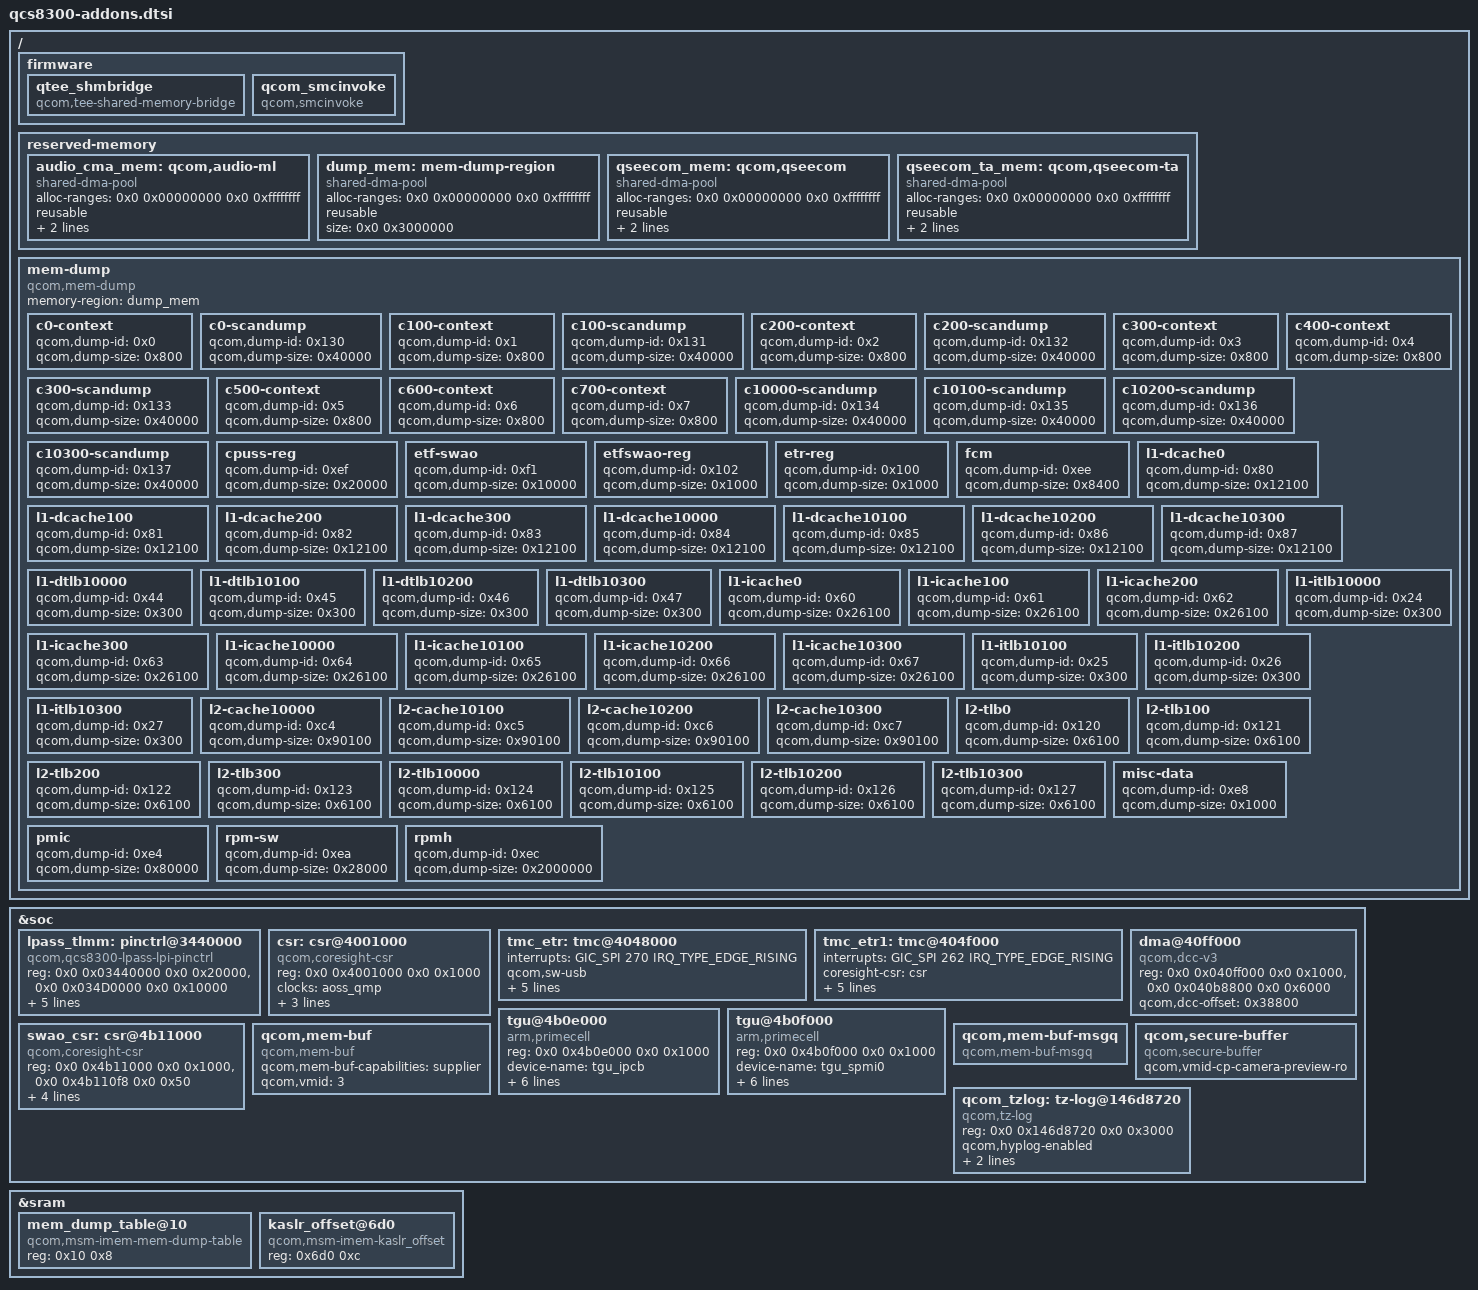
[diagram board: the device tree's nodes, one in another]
// SPDX-License-Identifier: BSD-3-Clause
/*
 * Copyright (c) 2024 Qualcomm Innovation Center, Inc. All rights reserved.
 */

#include "qcs8300-dma-heaps.dtsi"
/ {
	firmware {
		qtee_shmbridge {
			compatible = "qcom,tee-shared-memory-bridge";
		};

		qcom_smcinvoke {
			compatible = "qcom,smcinvoke";
		};
	};

	reserved-memory {
		audio_cma_mem: qcom,audio-ml {
			compatible = "shared-dma-pool";
			alloc-ranges = <0x0 0x00000000 0x0 0xffffffff>;
			reusable;
			alignment = <0x0 0x400000>;
			size = <0x0 0x1000000>;
		};

		dump_mem: mem-dump-region {
			compatible = "shared-dma-pool";
			alloc-ranges = <0x0 0x00000000 0x0 0xffffffff>;
			reusable;
			size = <0x0 0x3000000>;
		};

		qseecom_mem: qcom,qseecom {
			compatible = "shared-dma-pool";
			alloc-ranges = <0x0 0x00000000 0x0 0xffffffff>;
			reusable;
			alignment = <0x0 0x400000>;
			size = <0x0 0x1400000>; /* 20M */
		};

		qseecom_ta_mem: qcom,qseecom-ta {
			compatible = "shared-dma-pool";
			alloc-ranges = <0x0 0x00000000 0x0 0xffffffff>;
			reusable;
			alignment = <0x0 0x400000>;
			size = <0x0 0x1000000>; /* 16M */
		};
	};

	mem-dump {
		compatible = "qcom,mem-dump";
		memory-region = <&dump_mem>;

		c0-context {
			qcom,dump-id = <0x0>;
			qcom,dump-size = <0x800>;
		};

		c0-scandump {
			qcom,dump-id = <0x130>;
			qcom,dump-size = <0x40000>;
		};

		c100-context {
			qcom,dump-id = <0x1>;
			qcom,dump-size = <0x800>;
		};

		c100-scandump {
			qcom,dump-id = <0x131>;
			qcom,dump-size = <0x40000>;
		};

		c200-context {
			qcom,dump-id = <0x2>;
			qcom,dump-size = <0x800>;
		};

		c200-scandump {
			qcom,dump-id = <0x132>;
			qcom,dump-size = <0x40000>;
		};

		c300-context {
			qcom,dump-id = <0x3>;
			qcom,dump-size = <0x800>;
		};

		c300-scandump {
			qcom,dump-id = <0x133>;
			qcom,dump-size = <0x40000>;
		};

		c400-context {
			qcom,dump-id = <0x4>;
			qcom,dump-size = <0x800>;
		};

		c500-context {
			qcom,dump-id = <0x5>;
			qcom,dump-size = <0x800>;
		};

		c600-context {
			qcom,dump-id = <0x6>;
			qcom,dump-size = <0x800>;
		};

		c700-context {
			qcom,dump-id = <0x7>;
			qcom,dump-size = <0x800>;
		};

		c10000-scandump {
			qcom,dump-id = <0x134>;
			qcom,dump-size = <0x40000>;
		};

		c10100-scandump {
			qcom,dump-id = <0x135>;
			qcom,dump-size = <0x40000>;
		};

		c10200-scandump {
			qcom,dump-id = <0x136>;
			qcom,dump-size = <0x40000>;
		};

		c10300-scandump {
			qcom,dump-id = <0x137>;
			qcom,dump-size = <0x40000>;
		};

		cpuss-reg {
			qcom,dump-id = <0xef>;
			qcom,dump-size = <0x20000>;
		};

		etf-swao {
			qcom,dump-id = <0xf1>;
			qcom,dump-size = <0x10000>;
		};

		etfswao-reg {
			qcom,dump-id = <0x102>;
			qcom,dump-size = <0x1000>;
		};

		etr-reg {
			qcom,dump-id = <0x100>;
			qcom,dump-size = <0x1000>;
		};

		fcm {
			qcom,dump-id = <0xee>;
			qcom,dump-size = <0x8400>;
		};

		l1-dcache0 {
			qcom,dump-id = <0x80>;
			qcom,dump-size = <0x12100>;
		};

		l1-dcache100 {
			qcom,dump-id = <0x81>;
			qcom,dump-size = <0x12100>;
		};

		l1-dcache200 {
			qcom,dump-id = <0x82>;
			qcom,dump-size = <0x12100>;
		};

		l1-dcache300 {
			qcom,dump-id = <0x83>;
			qcom,dump-size = <0x12100>;
		};

		l1-dcache10000 {
			qcom,dump-id = <0x84>;
			qcom,dump-size = <0x12100>;
		};

		l1-dcache10100 {
			qcom,dump-id = <0x85>;
			qcom,dump-size = <0x12100>;
		};

		l1-dcache10200 {
			qcom,dump-id = <0x86>;
			qcom,dump-size = <0x12100>;
		};

		l1-dcache10300 {
			qcom,dump-id = <0x87>;
			qcom,dump-size = <0x12100>;
		};

		l1-dtlb10000 {
			qcom,dump-id = <0x44>;
			qcom,dump-size = <0x300>;
		};

		l1-dtlb10100 {
			qcom,dump-id = <0x45>;
			qcom,dump-size = <0x300>;
		};

		l1-dtlb10200 {
			qcom,dump-id = <0x46>;
			qcom,dump-size = <0x300>;
		};

		l1-dtlb10300 {
			qcom,dump-id = <0x47>;
			qcom,dump-size = <0x300>;
		};

		l1-icache0 {
			qcom,dump-id = <0x60>;
			qcom,dump-size = <0x26100>;
		};

		l1-icache100 {
			qcom,dump-id = <0x61>;
			qcom,dump-size = <0x26100>;
		};

		l1-icache200 {
			qcom,dump-id = <0x62>;
			qcom,dump-size = <0x26100>;
		};

		l1-icache300 {
			qcom,dump-id = <0x63>;
			qcom,dump-size = <0x26100>;
		};

		l1-icache10000 {
			qcom,dump-id = <0x64>;
			qcom,dump-size = <0x26100>;
		};

		l1-icache10100 {
			qcom,dump-id = <0x65>;
			qcom,dump-size = <0x26100>;
		};

		l1-icache10200 {
			qcom,dump-id = <0x66>;
			qcom,dump-size = <0x26100>;
		};

		l1-icache10300 {
			qcom,dump-id = <0x67>;
			qcom,dump-size = <0x26100>;
		};

		l1-itlb10000 {
			qcom,dump-id = <0x24>;
			qcom,dump-size = <0x300>;
		};

		l1-itlb10100 {
			qcom,dump-id = <0x25>;
			qcom,dump-size = <0x300>;
		};

		l1-itlb10200 {
			qcom,dump-id = <0x26>;
			qcom,dump-size = <0x300>;
		};

		l1-itlb10300 {
			qcom,dump-id = <0x27>;
			qcom,dump-size = <0x300>;
		};

		l2-cache10000 {
			qcom,dump-id = <0xc4>;
			qcom,dump-size = <0x90100>;
		};

		l2-cache10100 {
			qcom,dump-id = <0xc5>;
			qcom,dump-size = <0x90100>;
		};

		l2-cache10200 {
			qcom,dump-id = <0xc6>;
			qcom,dump-size = <0x90100>;
		};

		l2-cache10300 {
			qcom,dump-id = <0xc7>;
			qcom,dump-size = <0x90100>;
		};

		l2-tlb0 {
			qcom,dump-id = <0x120>;
			qcom,dump-size = <0x6100>;
		};

		l2-tlb100 {
			qcom,dump-id = <0x121>;
			qcom,dump-size = <0x6100>;
		};

		l2-tlb200 {
			qcom,dump-id = <0x122>;
			qcom,dump-size = <0x6100>;
		};

		l2-tlb300 {
			qcom,dump-id = <0x123>;
			qcom,dump-size = <0x6100>;
		};

		l2-tlb10000 {
			qcom,dump-id = <0x124>;
			qcom,dump-size = <0x6100>;
		};

		l2-tlb10100 {
			qcom,dump-id = <0x125>;
			qcom,dump-size = <0x6100>;
		};

		l2-tlb10200 {
			qcom,dump-id = <0x126>;
			qcom,dump-size = <0x6100>;
		};

		l2-tlb10300 {
			qcom,dump-id = <0x127>;
			qcom,dump-size = <0x6100>;
		};

		misc-data {
			qcom,dump-id = <0xe8>;
			qcom,dump-size = <0x1000>;
		};

		pmic {
			qcom,dump-id = <0xe4>;
			qcom,dump-size = <0x80000>;
		};

		rpm-sw {
			qcom,dump-id = <0xea>;
			qcom,dump-size = <0x28000>;
		};

		rpmh {
			qcom,dump-id = <0xec>;
			qcom,dump-size = <0x2000000>;
		};
	};
};

&soc {
	lpass_tlmm: pinctrl@3440000 {
		compatible = "qcom,qcs8300-lpass-lpi-pinctrl";
		reg = <0x0 0x03440000 0x0 0x20000>,
		      <0x0 0x034D0000 0x0 0x10000>;

		clocks = <&q6prmcc LPASS_HW_MACRO_VOTE LPASS_CLK_ATTRIBUTE_COUPLE_NO>,
			 <&q6prmcc LPASS_HW_DCODEC_VOTE LPASS_CLK_ATTRIBUTE_COUPLE_NO>;
		clock-names = "core", "audio";

		gpio-controller;
		#gpio-cells = <2>;
		gpio-ranges = <&lpass_tlmm 0 0 23>;
	};

	csr: csr@4001000 {
		compatible = "qcom,coresight-csr";
		reg = <0x0 0x4001000 0x0 0x1000>;
		reg-names = "csr-base";

		clocks = <&aoss_qmp>;
		clock-names = "apb_pclk";

		qcom,hwctrl-set-support;
		qcom,set-byte-cntr-support;
		qcom,blk-size = <1>;
	};

	tmc_etr: tmc@4048000 {
		interrupts = <GIC_SPI 270 IRQ_TYPE_EDGE_RISING>;
		interrupt-names = "byte-cntr-irq";
		qcom,sw-usb;
		coresight-csr = <&csr>;
		csr-atid-offset = <0xf8>;
		csr-irqctrl-offset = <0x6c>;
		byte-cntr-name = "byte-cntr";
		byte-cntr-class-name = "coresight-tmc-etr-stream";
	};

	tmc_etr1: tmc@404f000 {
		interrupts = <GIC_SPI 262 IRQ_TYPE_EDGE_RISING>;
		interrupt-names = "byte-cntr-irq";
		coresight-csr = <&csr>;
		csr-atid-offset = <0x108>;
		csr-irqctrl-offset = <0x70>;
		byte-cntr-name = "byte-cntr1";
		byte-cntr-class-name = "coresight-tmc-etr1-stream";
	};

	dma@40ff000 {
		compatible = "qcom,dcc-v3", "qcom,dcc";
		reg = <0x0 0x040ff000 0x0 0x1000>,
		      <0x0 0x040b8800 0x0 0x6000>;

		qcom,dcc-offset = <0x38800>;
	};

	tgu@4b0e000 {
		compatible = "arm,primecell", "qcom,coresight-tgu";
		reg = <0x0 0x4b0e000 0x0 0x1000>;
		reg-names = "tgu-base";
		device-name = "tgu_ipcb";

		clocks = <&aoss_qmp>;
		clock-names = "apb_pclk";

		arm,primecell-periphid = <0x0003b999>;
		tgu-conditions = <4>;
		tgu-regs = <4>;
		tgu-steps = <3>;
		tgu-timer-counters = <8>;
	};

	tgu@4b0f000 {
		compatible = "arm,primecell", "qcom,coresight-tgu";
		reg = <0x0 0x4b0f000 0x0 0x1000>;
		reg-names = "tgu-base";
		device-name = "tgu_spmi0";

		clocks = <&aoss_qmp>;
		clock-names = "apb_pclk";

		arm,primecell-periphid = <0x0003b999>;
		tgu-conditions = <4>;
		tgu-regs = <8>;
		tgu-steps = <3>;
		tgu-timer-counters = <8>;
	};

	swao_csr: csr@4b11000 {
		compatible = "qcom,coresight-csr";
		reg = <0x0 0x4b11000 0x0 0x1000>,
		      <0x0 0x4b110f8 0x0 0x50>;
		reg-names = "csr-base", "msr-base";

		clocks = <&aoss_qmp>;
		clock-names = "apb_pclk";

		qcom,timestamp-support;
		qcom,msr-support;
		qcom,blk-size = <1>;
	};

	qcom,mem-buf {
		compatible = "qcom,mem-buf";
		qcom,mem-buf-capabilities = "supplier";
		qcom,vmid = <3>;
	};

	qcom,mem-buf-msgq {
		compatible = "qcom,mem-buf-msgq";
	};

	qcom,secure-buffer {
		compatible = "qcom,secure-buffer";
		qcom,vmid-cp-camera-preview-ro;
	};

	qcom_tzlog: tz-log@146d8720 {
		compatible = "qcom,tz-log";
		reg = <0x0 0x146d8720 0x0 0x3000>;
		qcom,hyplog-enabled;
		hyplog-address-offset = <0x410>;
		hyplog-size-offset = <0x414>;
	};
};

&sram {
	mem_dump_table@10 {
		compatible = "qcom,msm-imem-mem-dump-table";
		reg = <0x10 0x8>;
	};

	kaslr_offset@6d0 {
		compatible = "qcom,msm-imem-kaslr_offset";
		reg = <0x6d0 0xc>;
	};
};
